# MKL81Z7 register map
Vendor: Freescale Semiconductor, Inc.; Series: Kinetis_L; File version: 1.6
CPU: CM0PLUS r0p0, little endian, no MPU, no FPU, VTOR, 2 interrupt priority bits
Registers are 32-bit, read-write, reset 0x0 unless marked. A register's access mark holds for its fields unless they carry their own. Offsets are from the block's base; [hi:lo] are bit positions; {n}, {i} and the like mark numbered series.

## DRY — Tamper Detect and Secure Key Storage
Base 0x40042000; register names take the prefix DRY_
0x04 SKVR — DryIce Secure Key Valid Register
  [7:0] SKV — Secure Key Valid
    0=Corresponding Secure Key Register has not been initialized since last invalidation, tamper or reset; 1=Corresponding Secure Key Register has been initialized since last invalidation, tamper or reset
0x08 SKWLR reset 0xFF — DryIce Secure Key Write Lock Register
  [7:0] SKWL — Secure Key Write Lock
    0=Corresponding Secure Key Register is locked and cannot be written by software; 1=Corresponding Secure Key Register can be written by software
0x0C SKRLR reset 0xFF — DryIce Secure Key Read Lock Register
  [7:0] SKRL — Secure Key Read Lock
    0=Corresponding Secure Key Register is locked and cannot be read by software; 1=Corresponding Secure Key Register can be read by software
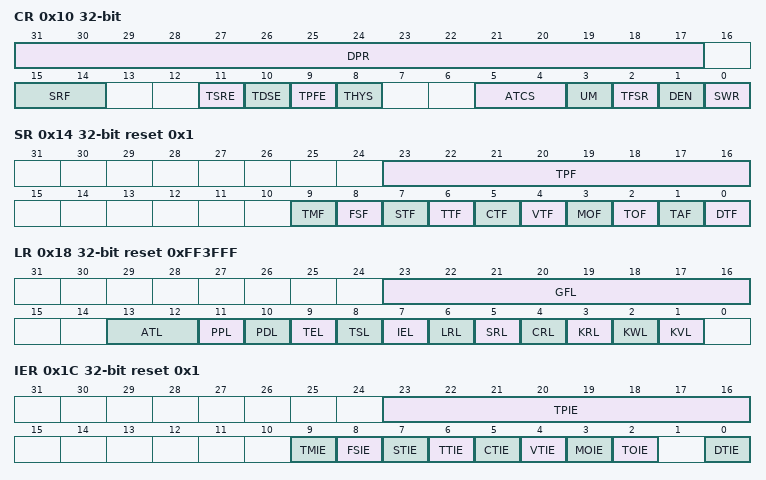
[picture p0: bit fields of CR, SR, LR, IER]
0x10 CR — DryIce Control Register
  [31:17] DPR — DryIce Prescaler Register
  [15:14] SRF — Secure Register File
    0=VBAT Register File is a general purpose register file, it is reset on VBAT POR only and can be accessed by supervisor or non-supervisor software; 2=VBAT Register File is a secure register file that is reset when DryIce Tamper Flag is set. It can only be accessed by software in supervisor mode.; 3=VBAT Register File is a secure register file that is reset when DryIce Tamper Flag is set or the DryIce Interrupt asserts. It can only be accessed by software in supervisor mode.
  [11] TSRE — Tamper Slew Rate Enable
    0=Tamper pins are configured for slow slew rate; 1=Tamper pins are configured for fast slew rate
  [10] TDSE — Tamper Drive Strength Enable
    0=Tamper pins are configured for low drive strength; 1=Tamper pins are configured for high drive strength
  [9] TPFE — Tamper Passive Filter Enable
    0=Tamper pins are configured with passive input filter disabled; 1=Tamper pins are configured with passive input filter enabled
  [8] THYS — Tamper Hysteresis Select
    0=Hysteresis is set to a range of 305 mV to 440 mV; 1=Hysteresis is set to a range of 490 mV to 705 mV
  [5:4] ATCS — Active Tamper Clock Source
    0=Active Tamper Shift Register clocked by 1 Hz prescaler clock; 1=Active Tamper Shift Register clocked by 512 Hz prescaler clock
  [3] UM — Update Mode
    0=DryIce Status Register cannot be written when the Status Register Lock bit within the Lock Register (LR[SRL]) is clear; 1=DryIce Status Register cannot be written when the Status Register Lock bit within the Lock Register (LR[SRL]) is clear and DryIce Tamper Flag (SR[DTF]) is set
  [2] TFSR — Tamper Force System Reset
    0=Do not force chip reset when tampering is detected; 1=Force chip reset when tampering is detected
  [1] DEN — DryIce Enable
    0=DryIce clock and prescaler are disabled; 1=DryIce clock and prescaler are enabled
  [0] SWR — Software Reset
    0=No effect; 1=Perform a software reset
0x14 SR reset 0x1 — DryIce Status Register
  [23:16] TPF — Tamper Pin Flag
    0=Tamper not detected; 1=Tamper pin tamper detected
  [9] TMF — Test Mode Flag
    0=Tamper not detected; 1=Test mode tamper detected
  [8] FSF — Flash Security Flag
    0=Tamper not detected; 1=Flash security tamper detected
  [7] STF — Security Tamper Flag
    0=Tamper not detected; 1=Security module tamper detected
  [6] TTF — Temperature Tamper Flag
    0=Tamper not detected; 1=Temperature tampering detected
  [5] CTF — Clock Tamper Flag
    0=Tamper not detected; 1=Clock tampering detected
  [4] VTF — Voltage Tamper Flag
    0=Tamper not detected; 1=Voltage tampering detected
  [3] MOF — Monotonic Overflow Flag
    0=Tamper not detected; 1=RTC monotonic overflow tamper detected
  [2] TOF — Time Overflow Flag
    0=Tamper not detected; 1=RTC time overflow tamper detected
  [1] TAF — Tamper Acknowledge Flag
    0=DryIce Tamper Flag (SR[DTF]) is clear or chip reset has not occurred after DryIce Tamper Flag (SR[DTF]) was set; 1=Chip reset has occurred after DryIce Tamper Flag (SR[DTF]) was set
  [0] DTF — DryIce Tamper Flag
    0=DryIce tampering not detected; 1=DryIce tampering detected
0x18 LR reset 0xFF3FFF — DryIce Lock Register
  [23:16] GFL — Glitch Filter Lock
    0=Pin glitch filter register is locked and writes are ignored; 1=Pin glitch filter register is not locked and writes complete as normal
  [13:12] ATL — Active Tamper Lock
    0=Active tamper register is locked and writes are ignored; 1=Active tamper register is not locked and writes complete as normal
  [11] PPL — Pin Polarity Lock
    0=Pin polarity register is locked and writes are ignored; 1=Pin polarity register is not locked and writes complete as normal
  [10] PDL — Pin Direction Lock
    0=Pin direction register is locked and writes are ignored; 1=Pin direction register is not locked and writes complete as normal
  [9] TEL — Tamper Enable Lock
    0=Tamper enable register is locked and writes are ignored; 1=Tamper enable register is not locked and writes complete as normal
  [8] TSL — Tamper Seconds Lock
    0=Tamper seconds register is locked and writes are ignored; 1=Tamper seconds register is not locked and writes complete as normal
  [7] IEL — Interrupt Enable Lock
    0=Interrupt enable register is locked and writes are ignored; 1=Interrupt enable register is not locked and writes complete as normal
  [6] LRL — Lock Register Lock
    0=Lock register is locked and writes are ignored; 1=Lock register is not locked and writes complete as normal
  [5] SRL — Status Register Lock
    0=Status Register is locked and writes are ignored; 1=Status Register is not locked and writes complete as normal
  [4] CRL — Control Register Lock
    0=Control register is locked and writes are ignored; 1=Control register is not locked and writes complete as normal
  [3] KRL — Key Read Lock
    0=Secure Key Read Lock Register is locked and writes are ignored; 1=Secure Key Read Lock Register is not locked and writes complete as normal
  [2] KWL — Key Write Lock
    0=Secure Key Write Lock Register is locked and writes are ignored; 1=Secure Key Write Lock Register is not locked and writes complete as normal
  [1] KVL — Key Valid Lock
    0=Secure key valid register is locked and writes are ignored; 1=Secure key valid register is not locked and writes complete as normal
0x1C IER reset 0x1 — DryIce Interrupt Enable Register
  [23:16] TPIE — Tamper Pin Interrupt Enable
    0=When corresponding tamper pin flag is set, an interrupt is not generated; 1=When corresponding tamper pin flag is set, an interrupt is generated
  [9] TMIE — Test Mode Interrupt Enable
    0=When test mode flag is set, an interrupt is not generated; 1=When test mode flag is set, an interrupt is generated
  [8] FSIE — Flash Security Interrupt Enable
    0=When flash security flag is set, an interrupt is not generated; 1=When flash security flag is set, an interrupt is generated
  [7] STIE — Security Tamper Interrupt Enable
    0=When security tamper flag is set, an interrupt is not generated; 1=When security tamper flag is set, an interrupt is generated
  [6] TTIE — Temperature Tamper Interrupt Enable
    0=When temperature tamper flag is set, an interrupt is not generated; 1=When temperature tamper flag is set, an interrupt is generated
  [5] CTIE — Clock Tamper Interrupt Enable
    0=When clock tamper flag is set, an interrupt is not generated; 1=When clock tamper flag is set, an interrupt is generated
  [4] VTIE — Voltage Tamper Interrupt Enable
    0=When voltage tamper flag is set, an interrupt is not generated; 1=When voltage tamper flag is set, an interrupt is generated
  [3] MOIE — Monotonic Overflow Interrupt Enable
    0=When monotonic overflow flag is set, an interrupt is not generated; 1=When monotonic overflow flag is set, an interrupt is generated
  [2] TOIE — Time Overflow Interrupt Enable
    0=When time overflow flag is set, an interrupt is not generated; 1=When time overflow flag is set, an interrupt is generated
  [0] DTIE — DryIce Tamper Interrupt Enable
    0=When DryIce Tamper Flag (SR[DTF]) is set, an interrupt is not generated; 1=When DryIce Tamper Flag (SR[DTF]) is set, an interrupt is generated
0x20 TSR — DryIce Tamper Seconds Register
  [31:0] TTS — Tamper Time Seconds
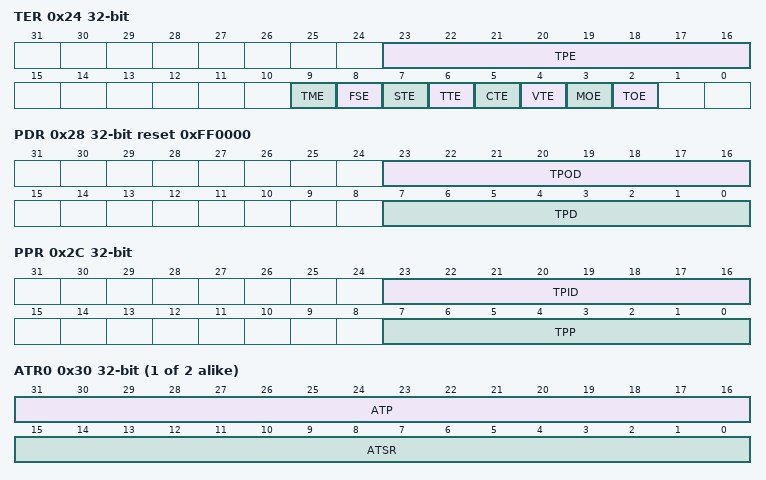
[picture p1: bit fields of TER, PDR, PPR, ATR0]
0x24 TER — DryIce Tamper Enable Register
  [23:16] TPE — Tamper Pin Enable
    0=When corresponding tamper pin flag is set, tampering is not detected; 1=When corresponding tamper pin flag is set, tampering is detected
  [9] TME — Test Mode Enable
    0=When test mode flag is set, tampering is not detected; 1=When test mode flag is set, tampering is detected
  [8] FSE — Flash Security Enable
    0=When flash security flag is set, tampering is not detected; 1=When flash security flag is set, tampering is detected
  [7] STE — Security Tamper Enable
    0=When security tamper flag is set, tampering is not detected; 1=When security tamper flag is set, tampering is detected
  [6] TTE — Temperature Tamper Enable
    0=When temperature tamper flag is set, tampering is not detected; 1=When temperature tamper flag is set, tampering is detected
  [5] CTE — Clock Tamper Enable
    0=When clock tamper flag is set, tampering is not detected; 1=When clock tamper flag is set, tampering is detected
  [4] VTE — Voltage Tamper Enable
    0=When voltage tamper flag is set, tampering is not detected; 1=When voltage tamper flag is set, tampering is detected
  [3] MOE — Monotonic Overflow Enable
    0=When monotonic overflow flag is set, tampering is not detected; 1=When monotonic overflow flag is set, tampering is detected
  [2] TOE — Time Overflow Enable
    0=When time overflow flag is set, tampering is not detected; 1=When time overflow flag is set, tampering is detected
0x28 PDR reset 0xFF0000 — DryIce Pin Direction Register
  [23:16] TPOD ro — Tamper Pin Output Data
    0=Tamper pin output data is logic zero; 1=Tamper pin output data is logic one
  [7:0] TPD — Tamper Pin Direction
    0=Tamper pin is input; 1=Tamper pin is output and drives inverse of expected value (tamper pin is asserted)
0x2C PPR — DryIce Pin Polarity Register
  [23:16] TPID ro — Tamper Pin Input Data
    0=Tamper pin input data (before glitch filter) is logic zero; 1=Tamper pin input data (before glitch filter) is logic one
  [7:0] TPP — Tamper Pin Polarity
    0=Tamper pin expected value is not inverted; 1=Tamper pin expected value is inverted
{0x30+4i} ATR{i} (i=0..1) — DryIce Active Tamper Register
  [31:16] ATP — Active Tamper Polynomial
  [15:0] ATSR — Active Tamper Shift Register
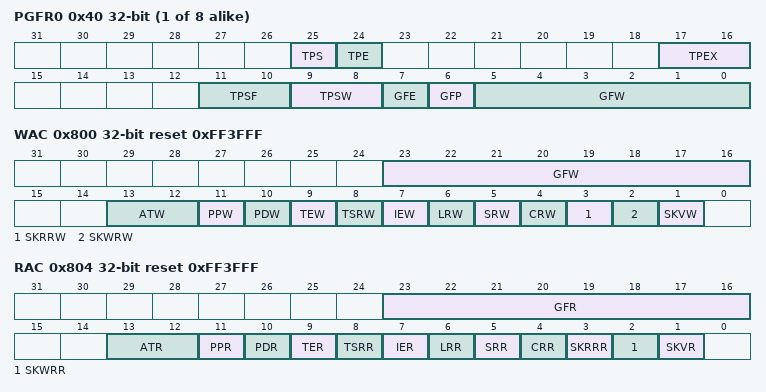
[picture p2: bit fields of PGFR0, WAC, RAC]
{0x40+4i} PGFR{i} (i=0..7) — DryIce Pin Glitch Filter Register
  [25] TPS — Tamper Pull Select
    0=Tamper pin pull direction will always assert the tamper pin; 1=Tamper pin pull direction will always negate the tamper pin
  [24] TPE — Tamper Pull Enable
    0=Pull resistor is disabled on tamper pin; 1=Pull resistor is enabled on tamper pin
  [17:16] TPEX — Tamper Pin Expected
    0=Tamper pin expected value is logic zero; 1=Tamper pin expected value is active tamper 0 output; 2=Tamper pin expected value is active tamper 1 output; 3=Tamper pin 0 expected value is active tamper 0 output XORed with active tamper 1 output
  [11:10] TPSF — Tamper Pin Sample Frequency
    0=Tamper Pin Sample Frequency is once every 8 cycles; 1=Tamper Pin Sample Frequency is once every 32 cycles; 2=Tamper Pin Sample Frequency is once every 128 cycles; 3=Tamper Pin Sample Frequency is once every 512 cycles
  [9:8] TPSW — Tamper Pin Sample Width
    0=Tamper Pin Sampling is disabled; 1=Tamper Pin Sample Width is 2 cycles for pull enable and 1 cycle for input buffer enable; 2=Tamper Pin Sample Width is 4 cycles for pull enable and 2 cycles for input buffer enable; 3=Tamper Pin Sample Width is 8 cycles for pull enable and 4 cycles for input buffer enable
  [7] GFE — Glitch Filter Enable
    0=The glitch filter on tamper pin is bypassed; 1=The glitch filter on tamper pin is enabled
  [6] GFP — Glitch Filter Prescaler
    0=The glitch filter on tamper pin is clocked by the 512 Hz prescaler clock; 1=The glitch filter on tamper pin is clocked by the 32.768 kHz clock
  [5:0] GFW — Glitch Filter Width
0x800 WAC reset 0xFF3FFF — DryIce Write Access Control Register
  [23:16] GFW — Glitch Filter Write
    0=Writes to the pin glitch filter register are ignored; 1=Writes to the pin glitch filter register complete as normal
  [13:12] ATW — Active Tamper Write
    0=Writes to the active tamper register are ignored; 1=Writes to the active tamper register complete as normal
  [11] PPW — Pin Polarity Write
    0=Writes to the pin polarity register are ignored; 1=Writes to the pin polarity register complete as normal
  [10] PDW — Pin Direction Write
    0=Writes to the pin direction register are ignored; 1=Writes to the pin direction register complete as normal
  [9] TEW — Tamper Enable Write
    0=Writes to the tamper enable register are ignored; 1=Writes to the tamper enable register complete as normal
  [8] TSRW — Tamper Seconds Register Write
    0=Writes to the Tamper Seconds register are ignored; 1=Writes to the Tamper Seconds register complete as normal
  [7] IEW — Interrupt Enable Write
    0=Writes to the Interrupt enable register are ignored; 1=Writes to the Interrupt enable register complete as normal
  [6] LRW — Lock Register Write
    0=Writes to the Lock register are ignored; 1=Writes to the Lock register complete as normal
  [5] SRW — Status Register Write
    0=Writes to the Status Register are ignored; 1=Writes to the Status Register complete as normal
  [4] CRW — Control Register Write
    0=Writes to the Control register are ignored; 1=Writes to the Control register complete as normal
  [3] SKRRW — Secure Key Read Lock Register Write
    0=Writes to the Secure Key Read Lock Register are ignored; 1=Writes to the Secure Key Read Lock Register complete as normal
  [2] SKWRW — Secure Key Write Lock Register Write
    0=Writes to the Secure Key Write Lock Register are ignored; 1=Writes to the Secure Key Write Lock Register complete as normal
  [1] SKVW — Secure Key Valid Write
    0=Writes to the secure key valid register are ignored; 1=Writes to the secure key valid register complete as normal
0x804 RAC reset 0xFF3FFF — DryIce Read Access Control Register
  [23:16] GFR — Glitch Filter Read
    0=Reads to the pin glitch filter register are ignored; 1=Reads to the pin glitch filter register complete as normal
  [13:12] ATR — Active Tamper Read
    0=Reads to the active tamper register are ignored; 1=Reads to the active tamper register complete as normal
  [11] PPR — Pin Polarity Read
    0=Reads to the pin polarity register are ignored; 1=Reads to the pin polarity register complete as normal
  [10] PDR — Pin Direction Read
    0=Reads to the pin direction register are ignored; 1=Reads to the pin direction register complete as normal
  [9] TER — Tamper Enable Read
    0=Reads to the tamper enable register are ignored; 1=Reads to the tamper enable register complete as normal
  [8] TSRR — Tamper Seconds Register Read
    0=Reads to the tamper seconds register are ignored; 1=Reads to the tamper seconds register complete as normal
  [7] IER — Interrupt Enable Read
    0=Reads to the Interrupt enable register are ignored; 1=Reads to the Interrupt enable register complete as normal
  [6] LRR — Lock Register Read
    0=Reads to the Lock register are ignored; 1=Reads to the Lock register complete as normal
  [5] SRR — Status Register Read
    0=Reads to the Status Register are ignored; 1=Reads to the Status Register complete as normal
  [4] CRR — Control Register Read
    0=Reads to the Control register are ignored; 1=Reads to the Control register complete as normal
  [3] SKRRR — Secure Key Read Lock Register Read
    0=Reads to the Secure Key Read Lock Register are ignored; 1=Reads to the Secure Key Read Lock Register complete as normal
  [2] SKWRR — Secure Key Write Lock Register Read
    0=Reads to the Secure Key Write Lock Register are ignored; 1=Reads to the Secure Key Write Lock Register complete as normal
  [1] SKVR — Secure Key Valid Read
    0=Reads to the secure key valid register are ignored; 1=Reads to the secure key valid register complete as normal
{0x1000+4i} SKR{i} (i=0..7) — Secure Key Register
  [31:0] SK — Secure Key
0x1800 SWAC reset 0xFF — Secure Write Access Control
  [7:0] SKRW — Secure Key Register Write
    0=Writes to the corresponding Secure Key Register are ignored; 1=Writes to the correspondingSecure Key Register complete as normal
0x1804 SRAC reset 0xFF — Secure Read Access Control
  [7:0] SKRR — Secure Key Register Read
    0=Reads to the corresponding Secure Key Register are ignored; 1=Reads to the corresponding Secure Key Register complete as normal
